AUTOSAR XML (schema 00049)
standard types defined: float32, uint16, uint8, float32_DataConstr, uint16_DataConstr, uint8_DataConstr
package /ComponentTypes
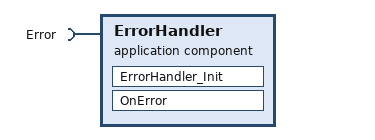
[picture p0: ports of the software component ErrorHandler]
  application sw component type ErrorHandler
    require port Error: nonqueued-receiver-com-spec{data-element=ErrorCode, filter=data-filter-type=ALWAYS}, required-interface=Error
    behavior ErrorHandler_InternalBehavior
      init event ErrorHandler_InitEvent: start-on-event=ErrorHandler_Init
      data received event DRT_OnError_Error_ErrorCode: start-on-event=OnError, data=Error.ErrorCode
      runnable ErrorHandler_Init
      runnable OnError
        data-receive-point-by-arguments:
          access REC_Error_ErrorCode: accessed-variable=Error.ErrorCode
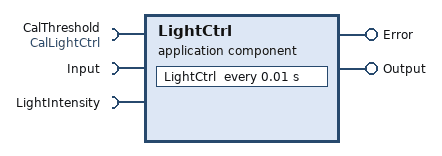
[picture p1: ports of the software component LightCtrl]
  application sw component type LightCtrl
    provide port Error: nonqueued-sender-com-spec{data-element=ErrorCode, init-value=0}, provided-interface=Error
    provide port Output: provided-com-specs=[{data-element=HeadLight, init-value=0}, {data-element=Temperature, init-value=72}], provided-interface=Output
    require port CalThreshold: required-interface=CalLightCtrl
      required-com-specs:
        init-value=70, parameter=Threshold_LightIntensityToOff
        init-value=60, parameter=Threshold_LightIntensityToOn
    require port Input: nonqueued-receiver-com-spec{data-element=LightSwitch, filter=data-filter-type=ALWAYS, init-value=0}, required-interface=Input
    require port LightIntensity: client-com-spec=LightIntensity, required-interface=LightIntensity
    behavior LightCtrl_InternalBehavior: data-type-mapping=TheTypeMappingSet
      timing event TMT_LightCtrl: start-on-event=LightCtrl, period=0.01
      implicit-inter-runnable-variables:
        data InterRunnableVariable: sw-calibration-access=READ-WRITE, type=float32, init-value=22
      runnable LightCtrl
        data-receive-point-by-arguments:
          access REC_Input_AlexSpecialPort_LightSwitch: accessed-variable=Input.LightSwitch
        data-send-points:
          access SEND_Error_ErrorCode: accessed-variable=Error.ErrorCode
          access SEND_Output_HeadLight: accessed-variable=Output.HeadLight
          access SEND_Output_Temperature: accessed-variable=Output.Temperature
        parameter access PA_CalThreshold_Threshold_LightIntensityToOff: accessed-parameter=CalThreshold.Threshold_LightIntensityToOff
        parameter access PA_CalThreshold_Threshold_LightIntensityToOn: accessed-parameter=CalThreshold.Threshold_LightIntensityToOn
        read-local-variables:
          access READ_InterRunnableVariable: accessed-variable=InterRunnableVariable
        sync call SC_LightIntensity_LightIntensity: operation=LightIntensity.LightIntensity, timeout=0
        written-local-variables:
          access WRITE_InterRunnableVariable: accessed-variable=InterRunnableVariable
  swc implementation ErrorHandler_Implementation: behavior=ErrorHandler_InternalBehavior
    code-descriptors:
      code Default: artifact-descriptors=autosar-engineering-object={short-label=Default, category=SWSRC}
  swc implementation LightCtrl_Implementation: behavior=LightCtrl_InternalBehavior
    code-descriptors:
      code Default: artifact-descriptors=autosar-engineering-object={short-label=Default, category=SWSRC}
package /ComponentTypes/DataTypeMappingSets
  data type mapping set TheTypeMappingSet: data-type-map{application-data-type=ADT_Temperature, implementation-data-type=float32}
package /DataTypes
  app type ADT_Temperature: category=VALUE, sw-calibration-access=READ-ONLY, compu {phys=raw*1.8+32 for raw -100..200, else 72; unit Degree}
  impl type ErrorCodeLightCtrl: category=VALUE, base-type=uint8, sw-calibration-access=READ-ONLY, compu {0=NoError, 1=ErrorLightIntensity, 2=ErrorLightSwitch, 3=ErrorThreshold, 4=ErrorInvalidState}, type-emitter=RTE
  impl type HeadLightEncoded: compu {0=Cx0_Off, 1=Cx1_On}, implementation-data-type=uint8, type-emitter=RTE
  impl type LightSwitchEncoded: compu {0=Cx0_Off, 1=Cx1_On, 2=Cx2_Auto, 3=Cx3_SNA} "Source signal range: [0,2]", implementation-data-type=uint8, type-emitter=RTE
package /DataTypes/Units
  unit Degree: display-name=Degree, factor-si-to-unit=1, offset-si-to-unit=0
package /ECUCompositionTypes
  composition sw component type ECU_Composition
    component ErrorHandler: type=ErrorHandler
    component LightCtrl: type=LightCtrl
    connect LightCtrl.Error -> ErrorHandler.Error
package /MICROSAR_SWCS_DEV/IoHwAb_swc/Interfaces
  client server interface LightIntensity
    operation LightIntensity
      arg io_signal: type=uint16, direction=OUT, server-argument-impl-policy=USE-ARGUMENT-TYPE
    error E_NOT_OK: error-code=1
package /PortInterfaces
  parameter interface CalLightCtrl
    parameter data prototype Threshold_LightIntensityToOff: sw-calibration-access=READ-WRITE, type=uint8
    parameter data prototype Threshold_LightIntensityToOn: sw-calibration-access=READ-WRITE, type=uint8
  sender receiver interface Error: invalidation-policy{data-element=ErrorCode, handle-invalid=DONT-INVALIDATE}
    data ErrorCode: type=ErrorCodeLightCtrl
  sender receiver interface Input: invalidation-policy{data-element=LightSwitch, handle-invalid=DONT-INVALIDATE}
    data LightSwitch: type=LightSwitchEncoded
  sender receiver interface Output
    data HeadLight: type=HeadLightEncoded
    data Temperature: type=ADT_Temperature
    invalidation-policys:
      data-element=HeadLight, handle-invalid=DONT-INVALIDATE
      data-element=Temperature, handle-invalid=DONT-INVALIDATE
